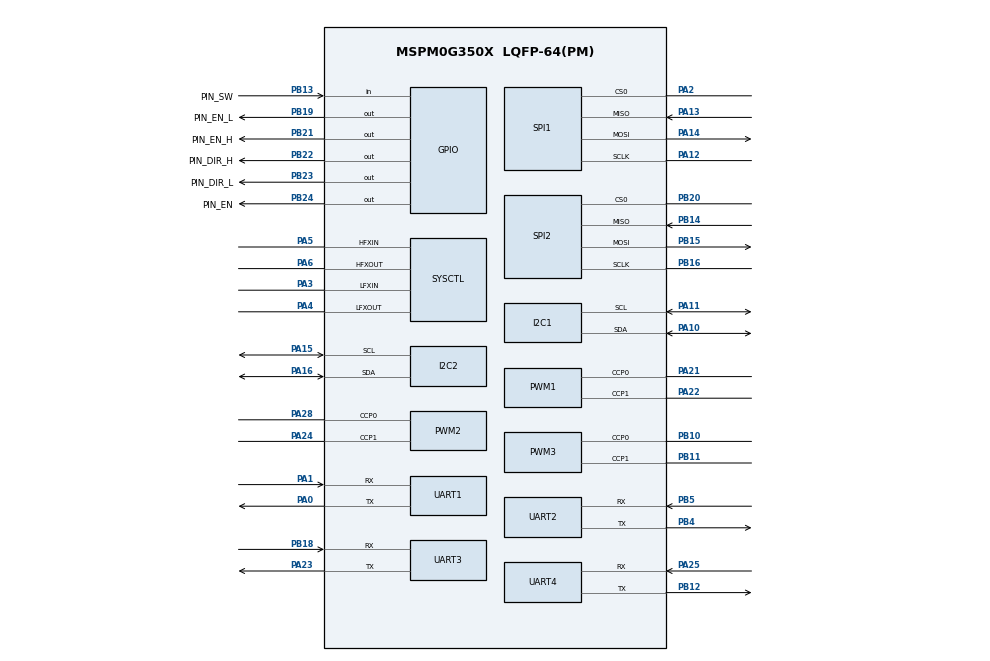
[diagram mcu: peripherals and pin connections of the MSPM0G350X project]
/**
 * @cliArgs --device "MSPM0G350X" --part "Default" --package "LQFP-64(PM)" --product "mspm0_sdk@2.05.01.01"
 * @versions {"tool":"1.24.1+4189"}
 */

/**
 * Import the modules used in this configuration.
 */
const ADC12  = scripting.addModule("/ti/driverlib/ADC12", {}, false);
const ADC121 = ADC12.addInstance();
const ADC122 = ADC12.addInstance();
const GPIO   = scripting.addModule("/ti/driverlib/GPIO", {}, false);
const GPIO1  = GPIO.addInstance();
const GPIO2  = GPIO.addInstance();
const GPIO3  = GPIO.addInstance();
const I2C    = scripting.addModule("/ti/driverlib/I2C", {}, false);
const I2C1   = I2C.addInstance();
const I2C2   = I2C.addInstance();
const PWM    = scripting.addModule("/ti/driverlib/PWM", {}, false);
const PWM1   = PWM.addInstance();
const PWM2   = PWM.addInstance();
const PWM3   = PWM.addInstance();
const SPI    = scripting.addModule("/ti/driverlib/SPI", {}, false);
const SPI1   = SPI.addInstance();
const SPI2   = SPI.addInstance();
const SYSCTL = scripting.addModule("/ti/driverlib/SYSCTL");
const UART   = scripting.addModule("/ti/driverlib/UART", {}, false);
const UART1  = UART.addInstance();
const UART2  = UART.addInstance();
const UART3  = UART.addInstance();
const UART4  = UART.addInstance();

/**
 * Write custom configuration values to the imported modules.
 */
ADC121.adcMem1chansel                    = "DL_ADC12_INPUT_CHAN_1";
ADC121.samplingOperationMode             = "sequence";
ADC121.sampClkSrc                        = "DL_ADC12_CLOCK_ULPCLK";
ADC121.adcMem2chansel                    = "DL_ADC12_INPUT_CHAN_2";
ADC121.endAdd                            = 1;
ADC121.adcMem0_name                      = "X";
ADC121.adcMem1_name                      = "Y";
ADC121.repeatMode                        = true;
ADC121.configureDMA                      = true;
ADC121.powerDownMode                     = "DL_ADC12_POWER_DOWN_MODE_MANUAL";
ADC121.sampleTime1                       = "0";
ADC121.sampleTime0                       = "200ns";
ADC121.enableFIFO                        = true;
ADC121.sampCnt                           = 6;
ADC121.enabledDMATriggers                = ["DL_ADC12_DMA_MEM10_RESULT_LOADED"];
ADC121.enabledInterrupts                 = ["DL_ADC12_INTERRUPT_DMA_DONE"];
ADC121.$name                             = "ADC12_JOYSTICK";
ADC121.adcPin0Config.$name               = "ti_driverlib_gpio_GPIOPinGeneric6";
ADC121.adcPin0Config.hideOutputInversion = scripting.forceWrite(false);
ADC121.adcPin1Config.$name               = "ti_driverlib_gpio_GPIOPinGeneric7";
ADC121.adcPin1Config.hideOutputInversion = scripting.forceWrite(false);
ADC121.peripheral.$assign                = "ADC0";
ADC121.peripheral.adcPin0.$assign        = "PA27";
ADC121.peripheral.adcPin1.$assign        = "PA26";
ADC121.DMA_CHANNEL.addressMode           = "f2b";
ADC121.DMA_CHANNEL.configureTransferSize = true;
ADC121.DMA_CHANNEL.transferMode          = "FULL_CH_REPEAT_SINGLE";
ADC121.DMA_CHANNEL.$name                 = "DMA_CH_ADC_JOYSTICK";
ADC121.DMA_CHANNEL.transferSize          = 6;
ADC121.DMA_CHANNEL.peripheral.$assign    = "DMA_CH0";

ADC122.sampClkSrc                        = "DL_ADC12_CLOCK_ULPCLK";
ADC122.adcMem0chansel                    = "DL_ADC12_INPUT_CHAN_4";
ADC122.$name                             = "ADC12_BATTERY";
ADC122.powerDownMode                     = "DL_ADC12_POWER_DOWN_MODE_MANUAL";
ADC122.sampleTime0                       = "100us";
ADC122.peripheral.$assign                = "ADC1";
ADC122.peripheral.adcPin4.$assign        = "PB17";
ADC122.adcPin4Config.$name               = "ti_driverlib_gpio_GPIOPinGeneric18";
ADC122.adcPin4Config.hideOutputInversion = scripting.forceWrite(false);

const Board = scripting.addModule("/ti/driverlib/Board", {}, false);

GPIO1.$name                              = "GPIO_JOYSTICK";
GPIO1.associatedPins[0].$name            = "PIN_SW";
GPIO1.associatedPins[0].direction        = "INPUT";
GPIO1.associatedPins[0].internalResistor = "PULL_UP";
GPIO1.associatedPins[0].pin.$assign      = "PB13";

GPIO2.$name                         = "GPIO_STEPPER_MOTOR";
GPIO2.associatedPins.create(4);
GPIO2.associatedPins[0].$name       = "PIN_EN_L";
GPIO2.associatedPins[0].pin.$assign = "PB19";
GPIO2.associatedPins[1].$name       = "PIN_EN_H";
GPIO2.associatedPins[1].pin.$assign = "PB21";
GPIO2.associatedPins[2].$name       = "PIN_DIR_H";
GPIO2.associatedPins[2].pin.$assign = "PB22";
GPIO2.associatedPins[3].$name       = "PIN_DIR_L";
GPIO2.associatedPins[3].pin.$assign = "PB23";

GPIO3.$name                          = "GPIO_BEEP";
GPIO3.associatedPins[0].$name        = "PIN_EN";
GPIO3.associatedPins[0].initialValue = "SET";
GPIO3.associatedPins[0].pin.$assign  = "PB24";

I2C1.$name                             = "OLED";
I2C1.basicEnableController             = true;
I2C1.peripheral.$assign                = "I2C0";
I2C1.peripheral.sdaPin.$assign         = "PA10";
I2C1.peripheral.sclPin.$assign         = "PA11";
I2C1.sdaPinConfig.hideOutputInversion  = scripting.forceWrite(false);
I2C1.sdaPinConfig.onlyInternalResistor = scripting.forceWrite(false);
I2C1.sdaPinConfig.passedPeripheralType = scripting.forceWrite("Digital");
I2C1.sdaPinConfig.$name                = "ti_driverlib_gpio_GPIOPinGeneric4";
I2C1.sclPinConfig.hideOutputInversion  = scripting.forceWrite(false);
I2C1.sclPinConfig.onlyInternalResistor = scripting.forceWrite(false);
I2C1.sclPinConfig.passedPeripheralType = scripting.forceWrite("Digital");
I2C1.sclPinConfig.$name                = "ti_driverlib_gpio_GPIOPinGeneric5";

I2C2.$name                             = "I2C_1";
I2C2.basicEnableController             = true;
I2C2.peripheral.$assign                = "I2C1";
I2C2.peripheral.sdaPin.$assign         = "PA16";
I2C2.peripheral.sclPin.$assign         = "PA15";
I2C2.sdaPinConfig.$name                = "ti_driverlib_gpio_GPIOPinGeneric10";
I2C2.sdaPinConfig.hideOutputInversion  = scripting.forceWrite(false);
I2C2.sdaPinConfig.onlyInternalResistor = scripting.forceWrite(false);
I2C2.sdaPinConfig.passedPeripheralType = scripting.forceWrite("Digital");
I2C2.sclPinConfig.$name                = "ti_driverlib_gpio_GPIOPinGeneric11";
I2C2.sclPinConfig.hideOutputInversion  = scripting.forceWrite(false);
I2C2.sclPinConfig.onlyInternalResistor = scripting.forceWrite(false);
I2C2.sclPinConfig.passedPeripheralType = scripting.forceWrite("Digital");

PWM1.$name                              = "STEPPER_MOTOR";
PWM1.pwmMode                            = "EDGE_ALIGN_UP";
PWM1.interrupts                         = ["LOAD_EVENT"];
PWM1.peripheral.$assign                 = "TIMA0";
PWM1.peripheral.ccp0Pin.$assign         = "PA21";
PWM1.peripheral.ccp1Pin.$assign         = "PA22";
PWM1.PWM_CHANNEL_0.$name                = "ti_driverlib_pwm_PWMTimerCC0";
PWM1.PWM_CHANNEL_0.dutyCycle            = 50;
PWM1.PWM_CHANNEL_1.$name                = "ti_driverlib_pwm_PWMTimerCC1";
PWM1.PWM_CHANNEL_1.dutyCycle            = 50;
PWM1.ccp0PinConfig.$name                = "ti_driverlib_gpio_GPIOPinGeneric2";
PWM1.ccp0PinConfig.direction            = scripting.forceWrite("OUTPUT");
PWM1.ccp0PinConfig.hideOutputInversion  = scripting.forceWrite(false);
PWM1.ccp0PinConfig.onlyInternalResistor = scripting.forceWrite(false);
PWM1.ccp0PinConfig.passedPeripheralType = scripting.forceWrite("Digital");
PWM1.ccp1PinConfig.$name                = "ti_driverlib_gpio_GPIOPinGeneric3";
PWM1.ccp1PinConfig.direction            = scripting.forceWrite("OUTPUT");
PWM1.ccp1PinConfig.hideOutputInversion  = scripting.forceWrite(false);
PWM1.ccp1PinConfig.onlyInternalResistor = scripting.forceWrite(false);
PWM1.ccp1PinConfig.passedPeripheralType = scripting.forceWrite("Digital");

PWM2.$name                              = "PWM_1";
PWM2.peripheral.$assign                 = "TIMA1";
PWM2.peripheral.ccp0Pin.$assign         = "PA28";
PWM2.peripheral.ccp1Pin.$assign         = "PA24";
PWM2.PWM_CHANNEL_0.$name                = "ti_driverlib_pwm_PWMTimerCC2";
PWM2.PWM_CHANNEL_1.$name                = "ti_driverlib_pwm_PWMTimerCC3";
PWM2.ccp0PinConfig.$name                = "ti_driverlib_gpio_GPIOPinGeneric12";
PWM2.ccp0PinConfig.direction            = scripting.forceWrite("OUTPUT");
PWM2.ccp0PinConfig.hideOutputInversion  = scripting.forceWrite(false);
PWM2.ccp0PinConfig.onlyInternalResistor = scripting.forceWrite(false);
PWM2.ccp0PinConfig.passedPeripheralType = scripting.forceWrite("Digital");
PWM2.ccp1PinConfig.$name                = "ti_driverlib_gpio_GPIOPinGeneric13";
PWM2.ccp1PinConfig.direction            = scripting.forceWrite("OUTPUT");
PWM2.ccp1PinConfig.hideOutputInversion  = scripting.forceWrite(false);
PWM2.ccp1PinConfig.onlyInternalResistor = scripting.forceWrite(false);
PWM2.ccp1PinConfig.passedPeripheralType = scripting.forceWrite("Digital");

PWM3.$name                              = "PWM_2";
PWM3.peripheral.$assign                 = "TIMG0";
PWM3.peripheral.ccp0Pin.$assign         = "PB10";
PWM3.peripheral.ccp1Pin.$assign         = "PB11";
PWM3.PWM_CHANNEL_0.$name                = "ti_driverlib_pwm_PWMTimerCC4";
PWM3.PWM_CHANNEL_1.$name                = "ti_driverlib_pwm_PWMTimerCC5";
PWM3.ccp0PinConfig.$name                = "ti_driverlib_gpio_GPIOPinGeneric27";
PWM3.ccp0PinConfig.direction            = scripting.forceWrite("OUTPUT");
PWM3.ccp0PinConfig.hideOutputInversion  = scripting.forceWrite(false);
PWM3.ccp0PinConfig.onlyInternalResistor = scripting.forceWrite(false);
PWM3.ccp0PinConfig.passedPeripheralType = scripting.forceWrite("Digital");
PWM3.ccp1PinConfig.$name                = "ti_driverlib_gpio_GPIOPinGeneric28";
PWM3.ccp1PinConfig.direction            = scripting.forceWrite("OUTPUT");
PWM3.ccp1PinConfig.hideOutputInversion  = scripting.forceWrite(false);
PWM3.ccp1PinConfig.onlyInternalResistor = scripting.forceWrite(false);
PWM3.ccp1PinConfig.passedPeripheralType = scripting.forceWrite("Digital");

SPI1.$name                      = "SPI_0";
SPI1.peripheral.$assign         = "SPI0";
SPI1.peripheral.sclkPin.$assign = "PA12";
SPI1.peripheral.mosiPin.$assign = "PA14";
SPI1.peripheral.misoPin.$assign = "PA13";
SPI1.peripheral.cs0Pin.$assign  = "PA2";
SPI1.sclkPinConfig.$name        = "ti_driverlib_gpio_GPIOPinGeneric14";
SPI1.mosiPinConfig.$name        = "ti_driverlib_gpio_GPIOPinGeneric15";
SPI1.misoPinConfig.$name        = "ti_driverlib_gpio_GPIOPinGeneric16";
SPI1.cs0PinConfig.$name         = "ti_driverlib_gpio_GPIOPinGeneric17";

SPI2.$name                      = "SPI_1";
SPI2.peripheral.$assign         = "SPI1";
SPI2.peripheral.sclkPin.$assign = "PB16";
SPI2.peripheral.mosiPin.$assign = "PB15";
SPI2.peripheral.misoPin.$assign = "PB14";
SPI2.peripheral.cs0Pin.$assign  = "PB20";
SPI2.sclkPinConfig.$name        = "ti_driverlib_gpio_GPIOPinGeneric19";
SPI2.mosiPinConfig.$name        = "ti_driverlib_gpio_GPIOPinGeneric20";
SPI2.misoPinConfig.$name        = "ti_driverlib_gpio_GPIOPinGeneric21";
SPI2.cs0PinConfig.$name         = "ti_driverlib_gpio_GPIOPinGeneric22";

SYSCTL.forceDefaultClkConfig        = true;
SYSCTL.HFCLKSource                  = "HFXT";
SYSCTL.useHFCLK_Manual              = true;
SYSCTL.HFCLK_Freq                   = 40000000;
SYSCTL.LFCLKSource                  = "LFXT";
SYSCTL.MCLKSource                   = "HSCLK";
SYSCTL.HSCLKSource                  = "HFCLK";
SYSCTL.peripheral.$assign           = "SYSCTL";
SYSCTL.peripheral.lfxInPin.$assign  = "PA3";
SYSCTL.peripheral.lfxOutPin.$assign = "PA4";
SYSCTL.peripheral.hfxInPin.$assign  = "PA5";
SYSCTL.peripheral.hfxOutPin.$assign = "PA6";
scripting.suppress("For best practices when the CPUCLK is running at 32MHz and above, clear the flash status bit using DL_FlashCTL_executeClearStatus\\(\\) before executing any flash operation\\. Otherwise there may be false positives\\.", SYSCTL);

UART1.$name                            = "K230";
UART1.enabledInterrupts                = ["RX"];
UART1.peripheral.$assign               = "UART0";
UART1.peripheral.rxPin.$assign         = "PA1";
UART1.peripheral.txPin.$assign         = "PA0";
UART1.txPinConfig.direction            = scripting.forceWrite("OUTPUT");
UART1.txPinConfig.hideOutputInversion  = scripting.forceWrite(false);
UART1.txPinConfig.onlyInternalResistor = scripting.forceWrite(false);
UART1.txPinConfig.passedPeripheralType = scripting.forceWrite("Digital");
UART1.txPinConfig.$name                = "ti_driverlib_gpio_GPIOPinGeneric0";
UART1.rxPinConfig.hideOutputInversion  = scripting.forceWrite(false);
UART1.rxPinConfig.onlyInternalResistor = scripting.forceWrite(false);
UART1.rxPinConfig.passedPeripheralType = scripting.forceWrite("Digital");
UART1.rxPinConfig.$name                = "ti_driverlib_gpio_GPIOPinGeneric1";

UART2.$name                            = "UART_1";
UART2.peripheral.$assign               = "UART1";
UART2.peripheral.rxPin.$assign         = "PB5";
UART2.peripheral.txPin.$assign         = "PB4";
UART2.txPinConfig.$name                = "ti_driverlib_gpio_GPIOPinGeneric8";
UART2.txPinConfig.direction            = scripting.forceWrite("OUTPUT");
UART2.txPinConfig.hideOutputInversion  = scripting.forceWrite(false);
UART2.txPinConfig.onlyInternalResistor = scripting.forceWrite(false);
UART2.txPinConfig.passedPeripheralType = scripting.forceWrite("Digital");
UART2.rxPinConfig.$name                = "ti_driverlib_gpio_GPIOPinGeneric9";
UART2.rxPinConfig.hideOutputInversion  = scripting.forceWrite(false);
UART2.rxPinConfig.onlyInternalResistor = scripting.forceWrite(false);
UART2.rxPinConfig.passedPeripheralType = scripting.forceWrite("Digital");

UART3.$name                            = "UART_2";
UART3.peripheral.$assign               = "UART2";
UART3.peripheral.rxPin.$assign         = "PB18";
UART3.peripheral.txPin.$assign         = "PA23";
UART3.txPinConfig.$name                = "ti_driverlib_gpio_GPIOPinGeneric23";
UART3.txPinConfig.direction            = scripting.forceWrite("OUTPUT");
UART3.txPinConfig.hideOutputInversion  = scripting.forceWrite(false);
UART3.txPinConfig.onlyInternalResistor = scripting.forceWrite(false);
UART3.txPinConfig.passedPeripheralType = scripting.forceWrite("Digital");
UART3.rxPinConfig.$name                = "ti_driverlib_gpio_GPIOPinGeneric24";
UART3.rxPinConfig.hideOutputInversion  = scripting.forceWrite(false);
UART3.rxPinConfig.onlyInternalResistor = scripting.forceWrite(false);
UART3.rxPinConfig.passedPeripheralType = scripting.forceWrite("Digital");

UART4.$name                            = "UART_3";
UART4.peripheral.$assign               = "UART3";
UART4.peripheral.rxPin.$assign         = "PA25";
UART4.peripheral.txPin.$assign         = "PB12";
UART4.txPinConfig.$name                = "ti_driverlib_gpio_GPIOPinGeneric25";
UART4.txPinConfig.direction            = scripting.forceWrite("OUTPUT");
UART4.txPinConfig.hideOutputInversion  = scripting.forceWrite(false);
UART4.txPinConfig.onlyInternalResistor = scripting.forceWrite(false);
UART4.txPinConfig.passedPeripheralType = scripting.forceWrite("Digital");
UART4.rxPinConfig.$name                = "ti_driverlib_gpio_GPIOPinGeneric26";
UART4.rxPinConfig.hideOutputInversion  = scripting.forceWrite(false);
UART4.rxPinConfig.onlyInternalResistor = scripting.forceWrite(false);
UART4.rxPinConfig.passedPeripheralType = scripting.forceWrite("Digital");

/**
 * Pinmux solution for unlocked pins/peripherals. This ensures that minor changes to the automatic solver in a future
 * version of the tool will not impact the pinmux you originally saw.  These lines can be completely deleted in order to
 * re-solve from scratch.
 */
Board.peripheral.$suggestSolution          = "DEBUGSS";
Board.peripheral.swclkPin.$suggestSolution = "PA20";
Board.peripheral.swdioPin.$suggestSolution = "PA19";
